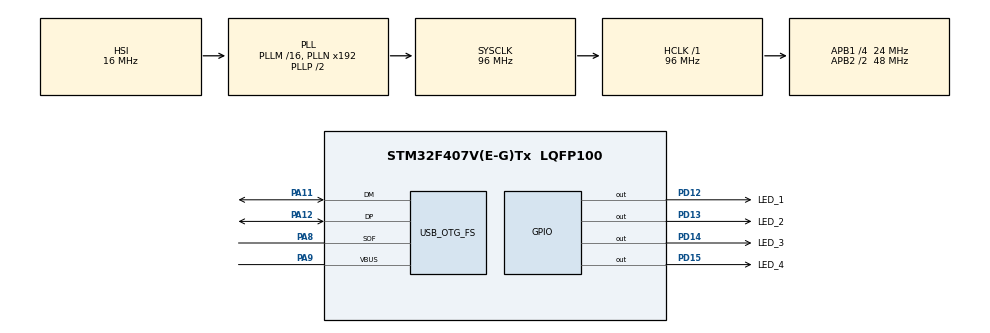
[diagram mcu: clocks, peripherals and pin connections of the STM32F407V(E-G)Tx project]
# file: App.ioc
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FREERTOS.Tasks01=FW_Update_Task,0,128,StartDefaultTask,Default,NULL,Dynamic,NULL,NULL;Led_Control,-3,128,StartTask02,Default,NULL,Dynamic,NULL,NULL;Motion_Sensor_R,-3,128,StartTask03,Default,NULL,Dynamic,NULL,NULL
Mcu.Family=STM32F4
Mcu.Name=STM32F407V(E-G)Tx
Mcu.Package=LQFP100
NVIC.OTG_FS_IRQn=true\:5\:0\:false\:false\:true\:true\:false\:true\:true
NVIC.PriorityGroup=NVIC_PRIORITYGROUP_4
NVIC.TIM1_UP_TIM10_IRQn=true\:15\:0\:false\:false\:true\:false\:false\:true\:true
NVIC.TimeBase=TIM1_UP_TIM10_IRQn
NVIC.TimeBaseIP=TIM1
PA11.Mode=Device_Only
PA11.Signal=USB_OTG_FS_DM
PA12.Mode=Device_Only
PA12.Signal=USB_OTG_FS_DP
PA13.Mode=Serial_Wire
PA13.Signal=SYS_JTMS-SWDIO
PA14.Mode=Serial_Wire
PA14.Signal=SYS_JTCK-SWCLK
PA8.Mode=Activate_SOF_FS
PA8.Signal=USB_OTG_FS_SOF
PA9.Mode=Activate_VBUS
PA9.Signal=USB_OTG_FS_VBUS
PD12.GPIO_Label=LED_1
PD12.Signal=GPIO_Output
PD13.GPIO_Label=LED_2
PD13.Signal=GPIO_Output
PD14.GPIO_Label=LED_3
PD14.Signal=GPIO_Output
PD15.GPIO_Label=LED_4
PD15.Signal=GPIO_Output
PH0-OSC_IN.Mode=HSE-External-Oscillator
PH0-OSC_IN.Signal=RCC_OSC_IN
PH1-OSC_OUT.Mode=HSE-External-Oscillator
PH1-OSC_OUT.Signal=RCC_OSC_OUT
ProjectManager.HeapSize=0x200
ProjectManager.StackSize=0x400
ProjectManager.TargetToolchain=STM32CubeIDE
RCC.AHBFreq_Value=96000000
RCC.APB1CLKDivider=RCC_HCLK_DIV4
RCC.APB1Freq_Value=24000000
RCC.APB1TimFreq_Value=48000000
RCC.APB2CLKDivider=RCC_HCLK_DIV2
RCC.APB2Freq_Value=48000000
RCC.APB2TimFreq_Value=96000000
RCC.CortexFreq_Value=96000000
RCC.HCLKFreq_Value=96000000
RCC.HSE_VALUE=8000000
RCC.HSI_VALUE=16000000
RCC.LSE_VALUE=32768
RCC.PLLSourceVirtualString=RCC_PLLSOURCE_HSI
RCC.SYSCLKFreq_VALUE=96000000
RCC.SYSCLKSource=RCC_SYSCLKSOURCE_PLLCLK
RCC.VCOOutputFreq_Value=192000000
USB_DEVICE.CLASS_NAME_FS=CDC
USB_DEVICE.VirtualMode-CDC_FS=Cdc
USB_DEVICE.VirtualModeFS=Cdc_FS
USB_OTG_FS.VirtualMode=Device_Only
VP_FREERTOS_VS_CMSIS_V1.Mode=CMSIS_V1
VP_SYS_VS_tim1.Mode=TIM1
VP_USB_DEVICE_VS_USB_DEVICE_CDC_FS.Mode=CDC_FS
board=custom

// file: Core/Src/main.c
/* USER CODE BEGIN Header */
/**
  ******************************************************************************
  * @file           : main.c
  * @brief          : Main program body
  ******************************************************************************
  * @attention
  *
  * Copyright (c) 2024 STMicroelectronics.
  * All rights reserved.
  *
  * This software is licensed under terms that can be found in the LICENSE file
  * in the root directory of this software component.
  * If no LICENSE file comes with this software, it is provided AS-IS.
  *
  ******************************************************************************
  */
/* USER CODE END Header */
#include "main.h"
#include "cmsis_os.h"
#include "usb_device.h"

osThreadId FW_Update_TaskHandle;
osThreadId Led_ControlHandle;
osThreadId Motion_Sensor_RHandle;

void SystemClock_Config(void);
static void MX_GPIO_Init(void);
void StartDefaultTask(void const * argument);
void StartTask02(void const * argument);
void StartTask03(void const * argument);

/* USER CODE BEGIN PFP */
void send_defTask(void)
{
	uint8_t data[] = "Default Task \r\n";
	CDC_Transmit_FS(data, sizeof(data));
}

void send_Task2(void)
{
	uint8_t data[] = " send Task 2 \r\n";
	CDC_Transmit_FS(data, sizeof(data));
}
/* USER CODE END PFP */

int main(void)
{

  /* MCU Configuration--------------------------------------------------------*/

  /* Reset of all peripherals, Initializes the Flash interface and the Systick. */
  HAL_Init();

  /* Configure the system clock */
  SystemClock_Config();

  /* Initialize all configured peripherals */
  MX_GPIO_Init();

  /* Create the thread(s) */
  /* definition and creation of FW_Update_Task */
  osThreadDef(FW_Update_Task, StartDefaultTask, osPriorityNormal, 0, 128);
  FW_Update_TaskHandle = osThreadCreate(osThread(FW_Update_Task), NULL);

  /* definition and creation of Led_Control */
  osThreadDef(Led_Control, StartTask02, osPriorityIdle, 0, 128);
  Led_ControlHandle = osThreadCreate(osThread(Led_Control), NULL);

  /* definition and creation of Motion_Sensor_R */
  osThreadDef(Motion_Sensor_R, StartTask03, osPriorityIdle, 0, 128);
  Motion_Sensor_RHandle = osThreadCreate(osThread(Motion_Sensor_R), NULL);

  /* Start scheduler */
  osKernelStart();
  /* We should never get here as control is now taken by the scheduler */
  /* Infinite loop */
  while (1)
  {

    /* USER CODE BEGIN 3 */
//	  HAL_GPIO_TogglePin(LED_1_GPIO_Port, LED_1_Pin);
//	  HAL_Delay(1);
  }
  /* USER CODE END 3 */
}

void SystemClock_Config(void)
{
  RCC_OscInitTypeDef RCC_OscInitStruct = {0};
  RCC_ClkInitTypeDef RCC_ClkInitStruct = {0};

  /** Configure the main internal regulator output voltage
  */
  __HAL_RCC_PWR_CLK_ENABLE();
  __HAL_PWR_VOLTAGESCALING_CONFIG(PWR_REGULATOR_VOLTAGE_SCALE1);

  /** Initializes the RCC Oscillators according to the specified parameters
  * in the RCC_OscInitTypeDef structure.
  */
  RCC_OscInitStruct.OscillatorType = RCC_OSCILLATORTYPE_HSI;
  RCC_OscInitStruct.HSIState = RCC_HSI_ON;
  RCC_OscInitStruct.HSICalibrationValue = RCC_HSICALIBRATION_DEFAULT;
  RCC_OscInitStruct.PLL.PLLState = RCC_PLL_ON;
  RCC_OscInitStruct.PLL.PLLSource = RCC_PLLSOURCE_HSI;
  RCC_OscInitStruct.PLL.PLLM = 16;
  RCC_OscInitStruct.PLL.PLLN = 192;
  RCC_OscInitStruct.PLL.PLLP = RCC_PLLP_DIV2;
  RCC_OscInitStruct.PLL.PLLQ = 4;
  if (HAL_RCC_OscConfig(&RCC_OscInitStruct) != HAL_OK)
  {
    Error_Handler();
  }

  /** Initializes the CPU, AHB and APB buses clocks
  */
  RCC_ClkInitStruct.ClockType = RCC_CLOCKTYPE_HCLK|RCC_CLOCKTYPE_SYSCLK
                              |RCC_CLOCKTYPE_PCLK1|RCC_CLOCKTYPE_PCLK2;
  RCC_ClkInitStruct.SYSCLKSource = RCC_SYSCLKSOURCE_PLLCLK;
  RCC_ClkInitStruct.AHBCLKDivider = RCC_SYSCLK_DIV1;
  RCC_ClkInitStruct.APB1CLKDivider = RCC_HCLK_DIV4;
  RCC_ClkInitStruct.APB2CLKDivider = RCC_HCLK_DIV2;

  if (HAL_RCC_ClockConfig(&RCC_ClkInitStruct, FLASH_LATENCY_3) != HAL_OK)
  {
    Error_Handler();
  }
}

static void MX_GPIO_Init(void)
{
  GPIO_InitTypeDef GPIO_InitStruct = {0};

  /* GPIO Ports Clock Enable */
  __HAL_RCC_GPIOH_CLK_ENABLE();
  __HAL_RCC_GPIOD_CLK_ENABLE();
  __HAL_RCC_GPIOA_CLK_ENABLE();

  /*Configure GPIO pin Output Level */
  HAL_GPIO_WritePin(GPIOD, LED_1_Pin|LED_2_Pin|LED_3_Pin|LED_4_Pin, GPIO_PIN_RESET);

  /*Configure GPIO pins : LED_1_Pin LED_2_Pin LED_3_Pin LED_4_Pin */
  GPIO_InitStruct.Pin = LED_1_Pin|LED_2_Pin|LED_3_Pin|LED_4_Pin;
  GPIO_InitStruct.Mode = GPIO_MODE_OUTPUT_PP;
  GPIO_InitStruct.Pull = GPIO_NOPULL;
  GPIO_InitStruct.Speed = GPIO_SPEED_FREQ_LOW;
  HAL_GPIO_Init(GPIOD, &GPIO_InitStruct);

}

void StartDefaultTask(void const * argument)
{
  /* init code for USB_DEVICE */
  MX_USB_DEVICE_Init();
  /* USER CODE BEGIN 5 */
  /* Infinite loop */
  for(;;)
  {
   // send_defTask();
    osDelay(1);
  }
  /* USER CODE END 5 */
}

void StartTask02(void const * argument)
{
  /* USER CODE BEGIN StartTask02 */
  /* Infinite loop */
  for(;;)
  {
	 send_Task2();
    HAL_GPIO_TogglePin(LED_1_GPIO_Port, LED_1_Pin);
    osDelay(1000);
  }
  /* USER CODE END StartTask02 */
}

void StartTask03(void const * argument)
{
  for(;;)
  {
    osDelay(1);
  }
}

void HAL_TIM_PeriodElapsedCallback(TIM_HandleTypeDef *htim)
{
  if (htim->Instance == TIM1) {
    HAL_IncTick();
  }
}

void Error_Handler(void)
{
  __disable_irq();
  while (1)
  {
  }
}
